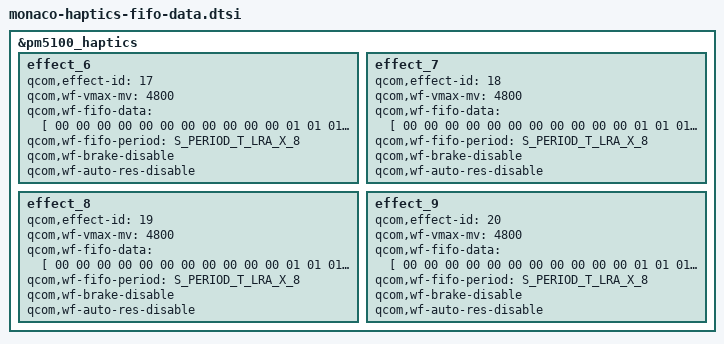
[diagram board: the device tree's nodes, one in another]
#include <dt-bindings/input/qcom,hv-haptics.h>

&pm5100_haptics {
	effect_6 {
		qcom,effect-id = <17>;
		qcom,wf-vmax-mv = <4800>;
		qcom,wf-fifo-data = [
			00 00 00 00 00 00 00 00 00 00
			00 01 01 01 01 01 01 01 01 01
			02 02 02 02 02 03 03 03 04 04
			04 05 05 05 06 06 07 08 08 09
			0a 0b 0c 0c 0d 0e 0f 0f 0f 0f
			0f 0f 0e 0e 0d 0c 0b 0a 09 08
			06 05 03 01 00 ff fd fa f8 f6
			f3 f1 ee ec e9 e6 e3 e0 dc d9
			d5 d1 cd c8 c4 bf bb b9 b7 b6
			b7 b8 ba bd c1 c5 cb d1 d7 de
			e5 ed f5 fd 04 0d 15 1e 26 2e
			36 3d 44 4b 51 56 5b 5f 62 64
			65 65 64 63 5f 5b 56 50 4a 45
			3f 3a 34 2f 29 24 1f 1a 14 0f
			0a 05 00 fc f8 f3 ef ea e6 e2
			df dc d9 d6 d4 d3 d2 d1 d1 d1
			d2 d4 d7 da de e2 e8 ee f6 fd
			02 08 0d 12 16 1a 1d 20 23 26
			28 2a 2b 2d 2e 2f 30 30 30 31
			31 31 31 30 30 2f 2f 2e 2d 2c
			2c 2b 2a 29 28 26 25 24 23 22
			21 20 1e 1d 1c 1b 1a 19 17 16
			15 14 13 12 11 10 0f 0e 0d 0c
			0b 0a 0a 09 08 07 07 06 05 04
			04 03 03 02 02 01 01 00 00 00
			00 00 ff ff ff ff fe fe fe fe
			fd fd fd fd fd fd fd fd fd fc
			fc fc fc fc fc fc fc fc fc fc
			fc fd fd fd fd fd fd fd fd fd
			fd fd fd fd fd fe fe fe fe fe
			fe fe fe fe fe fe ff ff ff ff
			ff ff ff ff ff ff ff ff ff ff
			00 00 00 00 00 00 00 00 00 00
			00 01 01 01 01 01 01 01 01 01
			02 02 02 02 02 03 03 03 04 04
			04 05 05 05 06 06 07 08 08 09
			0a 0b 0c 0c 0d 0e 0f 0f 0f 0f
			0f 0f 0e 0e 0d 0c 0b 0a 09 08
			06 05 03 01 00 ff fd fa f8 f6
			f3 f1 ee ec e9 e6 e3 e0 dc d9
			d5 d1 cd c8 c4 bf bb b9 b7 b6
			b7 b8 ba bd c1 c5 cb d1 d7 de
			e5 ed f5 fd 04 0d 15 1e 26 2e
			36 3d 44 4b 51 56 5b 5f 62 64
			65 65 64 63 5f 5b 56 50 4a 45
			3f 3a 34 2f 29 24 1f 1a 14 0f
			0a 05 00 fc f8 f3 ef ea e6 e2
			df dc d9 d6 d4 d3 d2 d1 d1 d1
			d2 d4 d7 da de e2 e8 ee f6 fd
			02 08 0d 12 16 1a 1d 20 23 26
			28 2a 2b 2d 2e 2f 30 30 30 31
			31 31 31 30 30 2f 2f 2e 2d 2c
			2c 2b 2a 29 28 26 25 24 23 22
			21 20 1e 1d 1c 1b 1a 19 17 16
			15 14 13 12 11 10 0f 0e 0d 0c
			0b 0a 0a 09 08 07 07 06 05 04
			04 03 03 02 02 01 01 00 00 00
			00 00 ff ff ff ff fe fe fe fe
			fd fd fd fd fd fd fd fd fd fc
			fc fc fc fc fc fc fc fc fc fc
			fc fd fd fd fd fd fd fd fd fd
			fd fd fd fd fd fe fe fe fe fe
			fe fe fe fe fe fe ff ff ff ff
			ff ff ff ff ff ff ff ff ff ff
			];
			qcom,wf-fifo-period = <S_PERIOD_T_LRA_X_8>;
			qcom,wf-brake-disable;
			qcom,wf-auto-res-disable;
	};

	effect_7 {
		qcom,effect-id = <18>;
		qcom,wf-vmax-mv = <4800>;
		qcom,wf-fifo-data = [
			00 00 00 00 00 00 00 00 00 00
			00 01 01 01 01 01 01 01 01 01
			02 02 02 02 02 03 03 03 04 04
			04 05 05 05 06 06 07 08 08 09
			0a 0b 0c 0c 0d 0e 0f 0f 0f 0f
			0f 0f 0e 0e 0d 0c 0b 0a 09 08
			06 05 03 01 00 ff fd fa f8 f6
			f3 f1 ee ec e9 e6 e3 e0 dc d9
			d5 d1 cd c8 c4 bf bb b9 b7 b6
			b7 b8 ba bd c1 c5 cb d1 d7 de
			e5 ed f5 fd 04 0d 15 1e 26 2e
			36 3d 44 4b 51 56 5b 5f 62 64
			65 65 64 63 5f 5b 56 50 4a 45
			3f 3a 34 2f 29 24 1f 1a 14 0f
			0a 05 00 fc f8 f3 ef ea e6 e2
			df dc d9 d6 d4 d3 d2 d1 d1 d1
			d2 d4 d7 da de e2 e8 ee f6 fd
			02 08 0d 12 16 1a 1d 20 23 26
			28 2a 2b 2d 2e 2f 30 30 30 31
			31 31 31 30 30 2f 2f 2e 2d 2c
			2c 2b 2a 29 28 26 25 24 23 22
			21 20 1e 1d 1c 1b 1a 19 17 16
			15 14 13 12 11 10 0f 0e 0d 0c
			0b 0a 0a 09 08 07 07 06 05 04
			04 03 03 02 02 01 01 00 00 00
			00 00 ff ff ff ff fe fe fe fe
			fd fd fd fd fd fd fd fd fd fc
			fc fc fc fc fc fc fc fc fc fc
			fc fd fd fd fd fd fd fd fd fd
			fd fd fd fd fd fe fe fe fe fe
			fe fe fe fe fe fe ff ff ff ff
			ff ff ff ff ff ff ff ff ff ff
			00 00 00 00 00 00 00 00 00 00
			00 01 01 01 01 01 01 01 01 01
			02 02 02 02 02 03 03 03 04 04
			04 05 05 05 06 06 07 08 08 09
			0a 0b 0c 0c 0d 0e 0f 0f 0f 0f
			0f 0f 0e 0e 0d 0c 0b 0a 09 08
			06 05 03 01 00 ff fd fa f8 f6
			f3 f1 ee ec e9 e6 e3 e0 dc d9
			d5 d1 cd c8 c4 bf bb b9 b7 b6
			b7 b8 ba bd c1 c5 cb d1 d7 de
			e5 ed f5 fd 04 0d 15 1e 26 2e
			36 3d 44 4b 51 56 5b 5f 62 64
			65 65 64 63 5f 5b 56 50 4a 45
			3f 3a 34 2f 29 24 1f 1a 14 0f
			0a 05 00 fc f8 f3 ef ea e6 e2
			df dc d9 d6 d4 d3 d2 d1 d1 d1
			d2 d4 d7 da de e2 e8 ee f6 fd
			02 08 0d 12 16 1a 1d 20 23 26
			28 2a 2b 2d 2e 2f 30 30 30 31
			31 31 31 30 30 2f 2f 2e 2d 2c
			2c 2b 2a 29 28 26 25 24 23 22
			21 20 1e 1d 1c 1b 1a 19 17 16
			15 14 13 12 11 10 0f 0e 0d 0c
			0b 0a 0a 09 08 07 07 06 05 04
			04 03 03 02 02 01 01 00 00 00
			00 00 ff ff ff ff fe fe fe fe
			fd fd fd fd fd fd fd fd fd fc
			fc fc fc fc fc fc fc fc fc fc
			fc fd fd fd fd fd fd fd fd fd
			fd fd fd fd fd fe fe fe fe fe
			fe fe fe fe fe fe ff ff ff ff
			ff ff ff ff ff ff ff ff ff ff
			];
			qcom,wf-fifo-period = <S_PERIOD_T_LRA_X_8>;
			qcom,wf-brake-disable;
			qcom,wf-auto-res-disable;
	};

	effect_8 {
		qcom,effect-id = <19>;
		qcom,wf-vmax-mv = <4800>;
		qcom,wf-fifo-data = [
			00 00 00 00 00 00 00 00 00 00
			00 01 01 01 01 01 01 01 01 01
			02 02 02 02 02 03 03 03 04 04
			04 05 05 05 06 06 07 08 08 09
			0a 0b 0c 0c 0d 0e 0f 0f 0f 0f
			0f 0f 0e 0e 0d 0c 0b 0a 09 08
			06 05 03 01 00 ff fd fa f8 f6
			f3 f1 ee ec e9 e6 e3 e0 dc d9
			d5 d1 cd c8 c4 bf bb b9 b7 b6
			b7 b8 ba bd c1 c5 cb d1 d7 de
			e5 ed f5 fd 04 0d 15 1e 26 2e
			36 3d 44 4b 51 56 5b 5f 62 64
			65 65 64 63 5f 5b 56 50 4a 45
			3f 3a 34 2f 29 24 1f 1a 14 0f
			0a 05 00 fc f8 f3 ef ea e6 e2
			df dc d9 d6 d4 d3 d2 d1 d1 d1
			d2 d4 d7 da de e2 e8 ee f6 fd
			02 08 0d 12 16 1a 1d 20 23 26
			28 2a 2b 2d 2e 2f 30 30 30 31
			31 31 31 30 30 2f 2f 2e 2d 2c
			2c 2b 2a 29 28 26 25 24 23 22
			21 20 1e 1d 1c 1b 1a 19 17 16
			15 14 13 12 11 10 0f 0e 0d 0c
			0b 0a 0a 09 08 07 07 06 05 04
			04 03 03 02 02 01 01 00 00 00
			00 00 ff ff ff ff fe fe fe fe
			fd fd fd fd fd fd fd fd fd fc
			fc fc fc fc fc fc fc fc fc fc
			fc fd fd fd fd fd fd fd fd fd
			fd fd fd fd fd fe fe fe fe fe
			fe fe fe fe fe fe ff ff ff ff
			ff ff ff ff ff ff ff ff ff ff
			00 00 00 00 00 00 00 00 00 00
			00 01 01 01 01 01 01 01 01 01
			02 02 02 02 02 03 03 03 04 04
			04 05 05 05 06 06 07 08 08 09
			0a 0b 0c 0c 0d 0e 0f 0f 0f 0f
			0f 0f 0e 0e 0d 0c 0b 0a 09 08
			06 05 03 01 00 ff fd fa f8 f6
			f3 f1 ee ec e9 e6 e3 e0 dc d9
			d5 d1 cd c8 c4 bf bb b9 b7 b6
			b7 b8 ba bd c1 c5 cb d1 d7 de
			e5 ed f5 fd 04 0d 15 1e 26 2e
			36 3d 44 4b 51 56 5b 5f 62 64
			65 65 64 63 5f 5b 56 50 4a 45
			3f 3a 34 2f 29 24 1f 1a 14 0f
			0a 05 00 fc f8 f3 ef ea e6 e2
			df dc d9 d6 d4 d3 d2 d1 d1 d1
			d2 d4 d7 da de e2 e8 ee f6 fd
			02 08 0d 12 16 1a 1d 20 23 26
			28 2a 2b 2d 2e 2f 30 30 30 31
			31 31 31 30 30 2f 2f 2e 2d 2c
			2c 2b 2a 29 28 26 25 24 23 22
			21 20 1e 1d 1c 1b 1a 19 17 16
			15 14 13 12 11 10 0f 0e 0d 0c
			0b 0a 0a 09 08 07 07 06 05 04
			04 03 03 02 02 01 01 00 00 00
			00 00 ff ff ff ff fe fe fe fe
			fd fd fd fd fd fd fd fd fd fc
			fc fc fc fc fc fc fc fc fc fc
			fc fd fd fd fd fd fd fd fd fd
			fd fd fd fd fd fe fe fe fe fe
			fe fe fe fe fe fe ff ff ff ff
			ff ff ff ff ff ff ff ff ff ff
			];
			qcom,wf-fifo-period = <S_PERIOD_T_LRA_X_8>;
			qcom,wf-brake-disable;
			qcom,wf-auto-res-disable;
	};

	effect_9 {
		qcom,effect-id = <20>;
		qcom,wf-vmax-mv = <4800>;
		qcom,wf-fifo-data = [
			00 00 00 00 00 00 00 00 00 00
			00 01 01 01 01 01 01 01 01 01
			02 02 02 02 02 03 03 03 04 04
			04 05 05 05 06 06 07 08 08 09
			0a 0b 0c 0c 0d 0e 0f 0f 0f 0f
			0f 0f 0e 0e 0d 0c 0b 0a 09 08
			06 05 03 01 00 ff fd fa f8 f6
			f3 f1 ee ec e9 e6 e3 e0 dc d9
			d5 d1 cd c8 c4 bf bb b9 b7 b6
			b7 b8 ba bd c1 c5 cb d1 d7 de
			e5 ed f5 fd 04 0d 15 1e 26 2e
			36 3d 44 4b 51 56 5b 5f 62 64
			65 65 64 63 5f 5b 56 50 4a 45
			3f 3a 34 2f 29 24 1f 1a 14 0f
			0a 05 00 fc f8 f3 ef ea e6 e2
			df dc d9 d6 d4 d3 d2 d1 d1 d1
			d2 d4 d7 da de e2 e8 ee f6 fd
			02 08 0d 12 16 1a 1d 20 23 26
			28 2a 2b 2d 2e 2f 30 30 30 31
			31 31 31 30 30 2f 2f 2e 2d 2c
			2c 2b 2a 29 28 26 25 24 23 22
			21 20 1e 1d 1c 1b 1a 19 17 16
			15 14 13 12 11 10 0f 0e 0d 0c
			0b 0a 0a 09 08 07 07 06 05 04
			04 03 03 02 02 01 01 00 00 00
			00 00 ff ff ff ff fe fe fe fe
			fd fd fd fd fd fd fd fd fd fc
			fc fc fc fc fc fc fc fc fc fc
			fc fd fd fd fd fd fd fd fd fd
			fd fd fd fd fd fe fe fe fe fe
			fe fe fe fe fe fe ff ff ff ff
			ff ff ff ff ff ff ff ff ff ff
			00 00 00 00 00 00 00 00 00 00
			00 01 01 01 01 01 01 01 01 01
			02 02 02 02 02 03 03 03 04 04
			04 05 05 05 06 06 07 08 08 09
			0a 0b 0c 0c 0d 0e 0f 0f 0f 0f
			0f 0f 0e 0e 0d 0c 0b 0a 09 08
			06 05 03 01 00 ff fd fa f8 f6
			f3 f1 ee ec e9 e6 e3 e0 dc d9
			d5 d1 cd c8 c4 bf bb b9 b7 b6
			b7 b8 ba bd c1 c5 cb d1 d7 de
			e5 ed f5 fd 04 0d 15 1e 26 2e
			36 3d 44 4b 51 56 5b 5f 62 64
			65 65 64 63 5f 5b 56 50 4a 45
			3f 3a 34 2f 29 24 1f 1a 14 0f
			0a 05 00 fc f8 f3 ef ea e6 e2
			df dc d9 d6 d4 d3 d2 d1 d1 d1
			d2 d4 d7 da de e2 e8 ee f6 fd
			02 08 0d 12 16 1a 1d 20 23 26
			28 2a 2b 2d 2e 2f 30 30 30 31
			31 31 31 30 30 2f 2f 2e 2d 2c
			2c 2b 2a 29 28 26 25 24 23 22
			21 20 1e 1d 1c 1b 1a 19 17 16
			15 14 13 12 11 10 0f 0e 0d 0c
			0b 0a 0a 09 08 07 07 06 05 04
			04 03 03 02 02 01 01 00 00 00
			00 00 ff ff ff ff fe fe fe fe
			fd fd fd fd fd fd fd fd fd fc
			fc fc fc fc fc fc fc fc fc fc
			fc fd fd fd fd fd fd fd fd fd
			fd fd fd fd fd fe fe fe fe fe
			fe fe fe fe fe fe ff ff ff ff
			ff ff ff ff ff ff ff ff ff ff
			];
			qcom,wf-fifo-period = <S_PERIOD_T_LRA_X_8>;
			qcom,wf-brake-disable;
			qcom,wf-auto-res-disable;
	};
};
